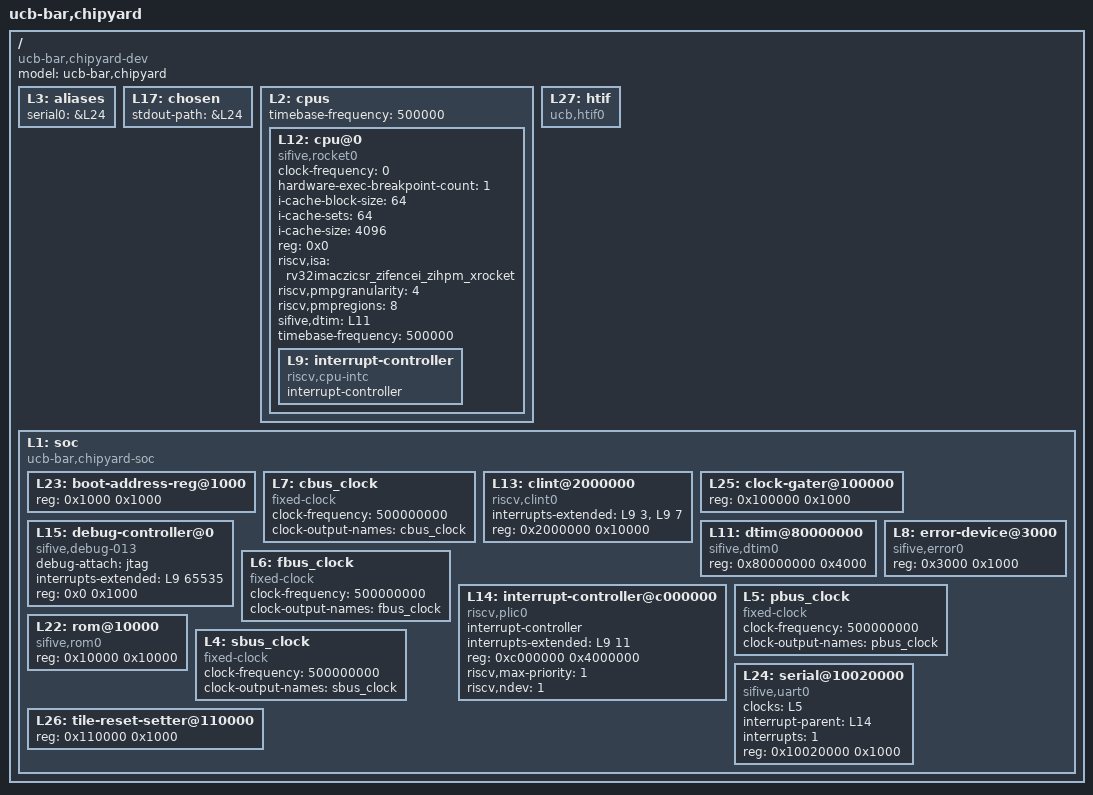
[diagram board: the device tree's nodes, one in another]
/dts-v1/;

/ {
	#address-cells = <1>;
	#size-cells = <1>;
	compatible = "ucb-bar,chipyard-dev";
	model = "ucb-bar,chipyard";
	L3: aliases {
		serial0 = &L24;
	};
	L17: chosen {
		stdout-path = &L24;
	};
	L2: cpus {
		#address-cells = <1>;
		#size-cells = <0>;
		timebase-frequency = <500000>;
		L12: cpu@0 {
			clock-frequency = <0>;
			compatible = "sifive,rocket0", "riscv";
			device_type = "cpu";
			hardware-exec-breakpoint-count = <1>;
			i-cache-block-size = <64>;
			i-cache-sets = <64>;
			i-cache-size = <4096>;
			reg = <0x0>;
			riscv,isa = "rv32imaczicsr_zifencei_zihpm_xrocket";
			riscv,pmpgranularity = <4>;
			riscv,pmpregions = <8>;
			sifive,dtim = <&L11>;
			status = "okay";
			timebase-frequency = <500000>;
			L9: interrupt-controller {
				#interrupt-cells = <1>;
				compatible = "riscv,cpu-intc";
				interrupt-controller;
			};
		};
	};
	L27: htif {
		compatible = "ucb,htif0";
	};
	L1: soc {
		#address-cells = <1>;
		#size-cells = <1>;
		compatible = "ucb-bar,chipyard-soc", "simple-bus";
		ranges;
		L23: boot-address-reg@1000 {
			reg = <0x1000 0x1000>;
			reg-names = "control";
		};
		L7: cbus_clock {
			#clock-cells = <0>;
			clock-frequency = <500000000>;
			clock-output-names = "cbus_clock";
			compatible = "fixed-clock";
		};
		L13: clint@2000000 {
			compatible = "riscv,clint0";
			interrupts-extended = <&L9 3 &L9 7>;
			reg = <0x2000000 0x10000>;
			reg-names = "control";
		};
		L25: clock-gater@100000 {
			reg = <0x100000 0x1000>;
			reg-names = "control";
		};
		L15: debug-controller@0 {
			compatible = "sifive,debug-013", "riscv,debug-013";
			debug-attach = "jtag";
			interrupts-extended = <&L9 65535>;
			reg = <0x0 0x1000>;
			reg-names = "control";
		};
		L11: dtim@80000000 {
			compatible = "sifive,dtim0";
			reg = <0x80000000 0x4000>;
			reg-names = "mem";
		};
		L8: error-device@3000 {
			compatible = "sifive,error0";
			reg = <0x3000 0x1000>;
		};
		L6: fbus_clock {
			#clock-cells = <0>;
			clock-frequency = <500000000>;
			clock-output-names = "fbus_clock";
			compatible = "fixed-clock";
		};
		L14: interrupt-controller@c000000 {
			#interrupt-cells = <1>;
			compatible = "riscv,plic0";
			interrupt-controller;
			interrupts-extended = <&L9 11>;
			reg = <0xc000000 0x4000000>;
			reg-names = "control";
			riscv,max-priority = <1>;
			riscv,ndev = <1>;
		};
		L5: pbus_clock {
			#clock-cells = <0>;
			clock-frequency = <500000000>;
			clock-output-names = "pbus_clock";
			compatible = "fixed-clock";
		};
		L22: rom@10000 {
			compatible = "sifive,rom0";
			reg = <0x10000 0x10000>;
			reg-names = "mem";
		};
		L4: sbus_clock {
			#clock-cells = <0>;
			clock-frequency = <500000000>;
			clock-output-names = "sbus_clock";
			compatible = "fixed-clock";
		};
		L24: serial@10020000 {
			clocks = <&L5>;
			compatible = "sifive,uart0";
			interrupt-parent = <&L14>;
			interrupts = <1>;
			reg = <0x10020000 0x1000>;
			reg-names = "control";
		};
		L26: tile-reset-setter@110000 {
			reg = <0x110000 0x1000>;
			reg-names = "control";
		};
	};
};
